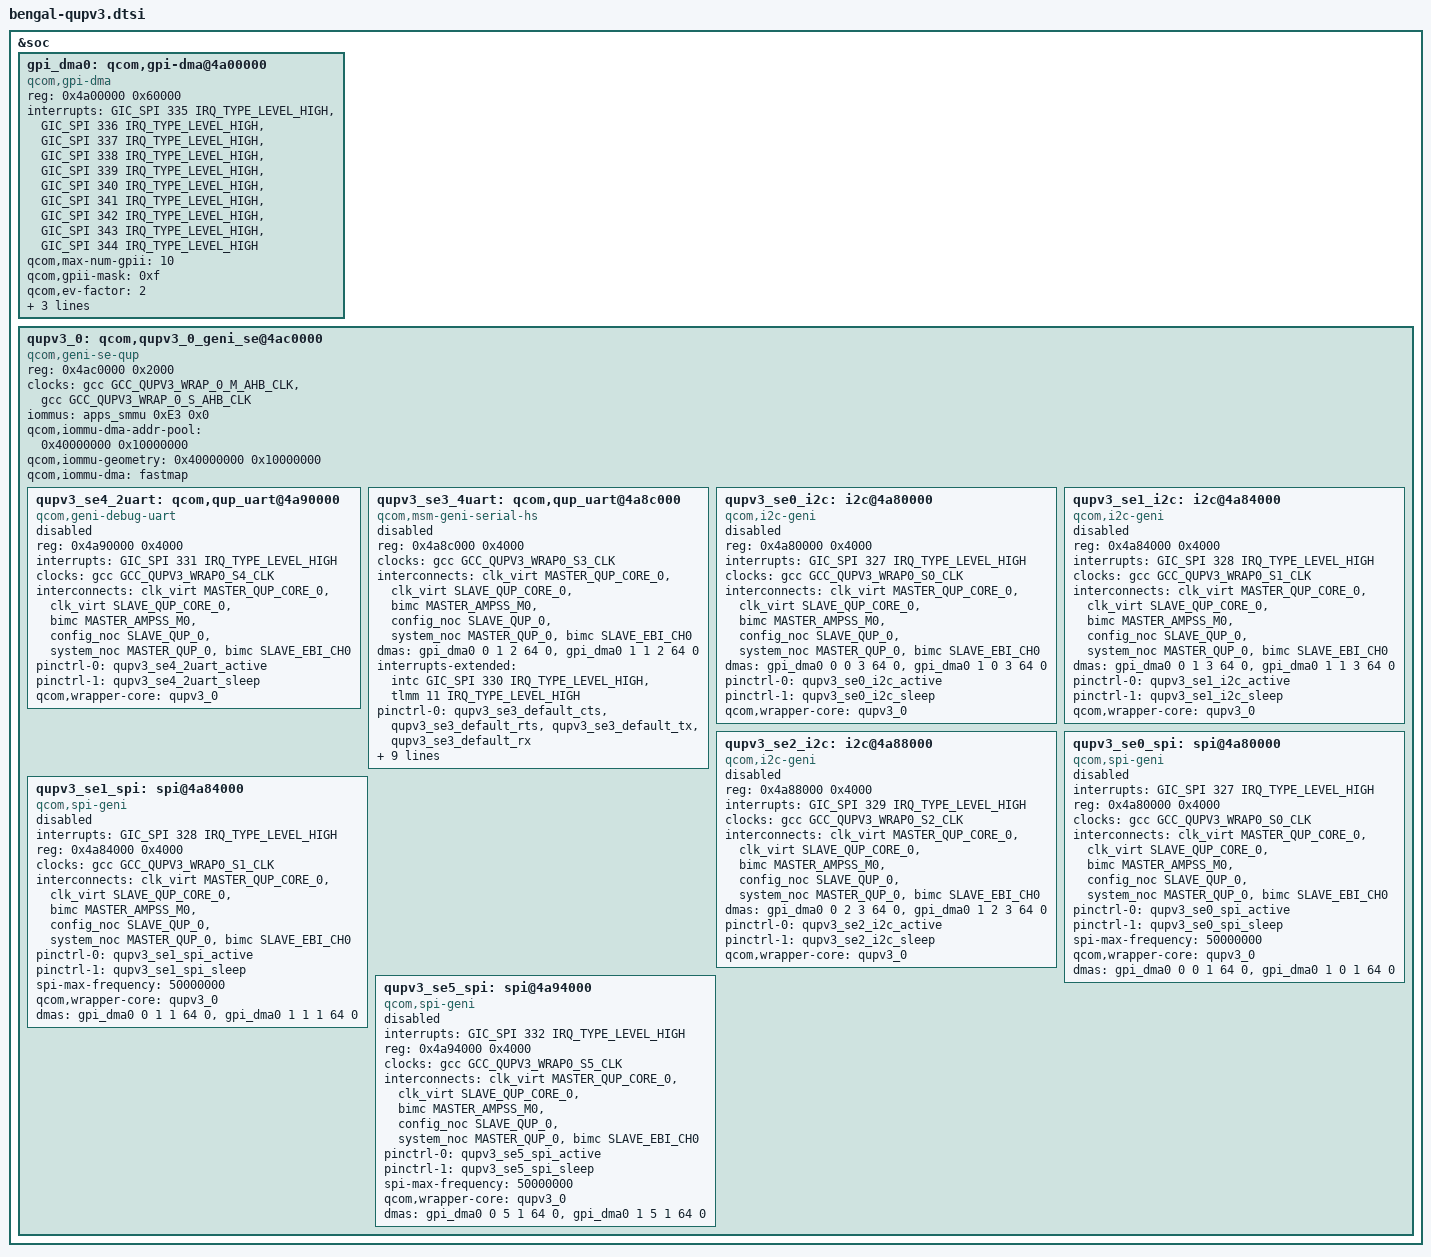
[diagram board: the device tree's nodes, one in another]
&soc {

	/* GPI Instance */
	gpi_dma0: qcom,gpi-dma@4a00000 {
		compatible = "qcom,gpi-dma";
		#dma-cells = <5>;
		reg = <0x4a00000 0x60000>;
		reg-names = "gpi-top";
		interrupts = <GIC_SPI 335 IRQ_TYPE_LEVEL_HIGH>,
			<GIC_SPI 336 IRQ_TYPE_LEVEL_HIGH>,
			<GIC_SPI 337 IRQ_TYPE_LEVEL_HIGH>,
			<GIC_SPI 338 IRQ_TYPE_LEVEL_HIGH>,
			<GIC_SPI 339 IRQ_TYPE_LEVEL_HIGH>,
			<GIC_SPI 340 IRQ_TYPE_LEVEL_HIGH>,
			<GIC_SPI 341 IRQ_TYPE_LEVEL_HIGH>,
			<GIC_SPI 342 IRQ_TYPE_LEVEL_HIGH>,
			<GIC_SPI 343 IRQ_TYPE_LEVEL_HIGH>,
			<GIC_SPI 344 IRQ_TYPE_LEVEL_HIGH>;
		qcom,max-num-gpii = <10>;
		qcom,gpii-mask = <0xf>;
		qcom,ev-factor = <2>;
		iommus = <&apps_smmu 0xf6 0x0>;
		qcom,gpi-ee-offset = <0x10000>;
		qcom,iommu-dma-addr-pool = <0x100000 0x100000>;
		status = "ok";
	};

	/* QUPv3_0  wrapper  instance */
	qupv3_0: qcom,qupv3_0_geni_se@4ac0000 {
		compatible = "qcom,geni-se-qup";
		reg = <0x4ac0000 0x2000>;
		#address-cells = <1>;
		#size-cells = <1>;
		clock-names = "m-ahb", "s-ahb";
		clocks = <&gcc GCC_QUPV3_WRAP_0_M_AHB_CLK>,
			<&gcc GCC_QUPV3_WRAP_0_S_AHB_CLK>;
		iommus = <&apps_smmu 0xE3 0x0>;
		qcom,iommu-dma-addr-pool = <0x40000000 0x10000000>;
		qcom,iommu-geometry = <0x40000000 0x10000000>;
		qcom,iommu-dma = "fastmap";
		ranges;
		status = "ok";

		/* Debug UART Instance */
		qupv3_se4_2uart: qcom,qup_uart@4a90000 {
			compatible = "qcom,geni-debug-uart";
			reg = <0x4a90000 0x4000>;
			reg-names = "se_phys";
			interrupts = <GIC_SPI 331 IRQ_TYPE_LEVEL_HIGH>;
			clock-names = "se";
			clocks = <&gcc GCC_QUPV3_WRAP0_S4_CLK>;
			interconnect-names = "qup-core", "qup-config", "qup-memory";
			interconnects = <&clk_virt MASTER_QUP_CORE_0 &clk_virt SLAVE_QUP_CORE_0>,
			<&bimc MASTER_AMPSS_M0 &config_noc SLAVE_QUP_0>,
			<&system_noc MASTER_QUP_0 &bimc SLAVE_EBI_CH0>;
			pinctrl-names = "default", "sleep";
			pinctrl-0 = <&qupv3_se4_2uart_active>;
			pinctrl-1 = <&qupv3_se4_2uart_sleep>;
			qcom,wrapper-core = <&qupv3_0>;
			status = "disabled";
		};

		/* HS UART Instance */
		qupv3_se3_4uart: qcom,qup_uart@4a8c000 {
			compatible = "qcom,msm-geni-serial-hs";
			reg = <0x4a8c000 0x4000>;
			reg-names = "se_phys";
			clock-names = "se-clk";
			clocks = <&gcc GCC_QUPV3_WRAP0_S3_CLK>;
			interconnect-names = "qup-core", "qup-config", "qup-memory";
			interconnects = <&clk_virt MASTER_QUP_CORE_0 &clk_virt SLAVE_QUP_CORE_0>,
			<&bimc MASTER_AMPSS_M0 &config_noc SLAVE_QUP_0>,
			<&system_noc MASTER_QUP_0 &bimc SLAVE_EBI_CH0>;
			dmas = <&gpi_dma0 0 1 2 64 0>,
			<&gpi_dma0 1 1 2 64 0>;
			dma-names = "tx", "rx";
			pinctrl-names = "default", "active", "sleep", "shutdown";
			interrupts-extended = <&intc GIC_SPI 330 IRQ_TYPE_LEVEL_HIGH>,
					<&tlmm 11 IRQ_TYPE_LEVEL_HIGH>;
			pinctrl-0 = <&qupv3_se3_default_cts>, <&qupv3_se3_default_rts>,
				<&qupv3_se3_default_tx>, <&qupv3_se3_default_rx>;
			pinctrl-1 = <&qupv3_se3_cts>, <&qupv3_se3_rts>,
				<&qupv3_se3_tx>, <&qupv3_se3_rx>;
			pinctrl-2 = <&qupv3_se3_cts>, <&qupv3_se3_rts>,
				<&qupv3_se3_tx>, <&qupv3_se3_default_rx>;
			pinctrl-3 = <&qupv3_se3_default_cts>, <&qupv3_se3_default_rts>,
				<&qupv3_se3_default_tx>, <&qupv3_se3_default_rx>;
			qcom,wrapper-core = <&qupv3_0>;
			qcom,wakeup-byte = <0xFD>;
			status = "disabled";
		};

		/* I2C Instance */
		qupv3_se0_i2c: i2c@4a80000 {
			compatible = "qcom,i2c-geni";
			reg = <0x4a80000 0x4000>;
			#address-cells = <1>;
			#size-cells = <0>;
			interrupts = <GIC_SPI 327 IRQ_TYPE_LEVEL_HIGH>;
			clock-names = "se-clk";
			clocks = <&gcc GCC_QUPV3_WRAP0_S0_CLK>;
			interconnect-names = "qup-core", "qup-config", "qup-memory";
			interconnects = <&clk_virt MASTER_QUP_CORE_0 &clk_virt SLAVE_QUP_CORE_0>,
			<&bimc MASTER_AMPSS_M0 &config_noc SLAVE_QUP_0>,
			<&system_noc MASTER_QUP_0 &bimc SLAVE_EBI_CH0>;
			dmas = <&gpi_dma0 0 0 3 64 0>,
				<&gpi_dma0 1 0 3 64 0>;
			dma-names = "tx", "rx";
			pinctrl-names = "default", "sleep";
			pinctrl-0 = <&qupv3_se0_i2c_active>;
			pinctrl-1 = <&qupv3_se0_i2c_sleep>;
			qcom,wrapper-core = <&qupv3_0>;
			status = "disabled";
		};

		/* I2C Instance */
		qupv3_se1_i2c: i2c@4a84000 {
			compatible = "qcom,i2c-geni";
			reg = <0x4a84000 0x4000>;
			#address-cells = <1>;
			#size-cells = <0>;
			interrupts = <GIC_SPI 328 IRQ_TYPE_LEVEL_HIGH>;
			clock-names = "se-clk";
			clocks = <&gcc GCC_QUPV3_WRAP0_S1_CLK>;
			interconnect-names = "qup-core", "qup-config", "qup-memory";
			interconnects = <&clk_virt MASTER_QUP_CORE_0 &clk_virt SLAVE_QUP_CORE_0>,
			<&bimc MASTER_AMPSS_M0 &config_noc SLAVE_QUP_0>,
			<&system_noc MASTER_QUP_0 &bimc SLAVE_EBI_CH0>;
			dmas = <&gpi_dma0 0 1 3 64 0>,
				<&gpi_dma0 1 1 3 64 0>;
			dma-names = "tx", "rx";
			pinctrl-names = "default", "sleep";
			pinctrl-0 = <&qupv3_se1_i2c_active>;
			pinctrl-1 = <&qupv3_se1_i2c_sleep>;
			qcom,wrapper-core = <&qupv3_0>;
			status = "disabled";
		};

		/* I2C Instance */
		qupv3_se2_i2c: i2c@4a88000 {
			compatible = "qcom,i2c-geni";
			reg = <0x4a88000 0x4000>;
			#address-cells = <1>;
			#size-cells = <0>;
			interrupts = <GIC_SPI 329 IRQ_TYPE_LEVEL_HIGH>;
			clock-names = "se-clk";
			clocks = <&gcc GCC_QUPV3_WRAP0_S2_CLK>;
			interconnect-names = "qup-core", "qup-config", "qup-memory";
			interconnects = <&clk_virt MASTER_QUP_CORE_0 &clk_virt SLAVE_QUP_CORE_0>,
			<&bimc MASTER_AMPSS_M0 &config_noc SLAVE_QUP_0>,
			<&system_noc MASTER_QUP_0 &bimc SLAVE_EBI_CH0>;
			dmas = <&gpi_dma0 0 2 3 64 0>,
				<&gpi_dma0 1 2 3 64 0>;
			dma-names = "tx", "rx";
			pinctrl-names = "default", "sleep";
			pinctrl-0 = <&qupv3_se2_i2c_active>;
			pinctrl-1 = <&qupv3_se2_i2c_sleep>;
			qcom,wrapper-core = <&qupv3_0>;
			status = "disabled";
		};

		/* SPI Instance */
		qupv3_se0_spi: spi@4a80000 {
			compatible = "qcom,spi-geni";
			#address-cells = <1>;
			#size-cells = <0>;
			interrupts = <GIC_SPI 327 IRQ_TYPE_LEVEL_HIGH>;
			reg = <0x4a80000 0x4000>;
			reg-names = "se_phys";
			clock-names = "se-clk";
			clocks = <&gcc GCC_QUPV3_WRAP0_S0_CLK>;
			interconnect-names = "qup-core", "qup-config", "qup-memory";
			interconnects = <&clk_virt MASTER_QUP_CORE_0 &clk_virt SLAVE_QUP_CORE_0>,
			<&bimc MASTER_AMPSS_M0 &config_noc SLAVE_QUP_0>,
			<&system_noc MASTER_QUP_0 &bimc SLAVE_EBI_CH0>;
			pinctrl-names = "default", "sleep";
			pinctrl-0 = <&qupv3_se0_spi_active>;
			pinctrl-1 = <&qupv3_se0_spi_sleep>;
			spi-max-frequency = <50000000>;
			qcom,wrapper-core = <&qupv3_0>;
			dmas = <&gpi_dma0 0 0 1 64 0>,
				<&gpi_dma0 1 0 1 64 0>;
			dma-names = "tx", "rx";
			status = "disabled";
		};

		/* SPI Instance */
		qupv3_se1_spi: spi@4a84000 {
			compatible = "qcom,spi-geni";
			#address-cells = <1>;
			#size-cells = <0>;
			interrupts = <GIC_SPI 328 IRQ_TYPE_LEVEL_HIGH>;
			reg = <0x4a84000 0x4000>;
			reg-names = "se_phys";
			clock-names = "se-clk";
			clocks = <&gcc GCC_QUPV3_WRAP0_S1_CLK>;
			interconnect-names = "qup-core", "qup-config", "qup-memory";
			interconnects = <&clk_virt MASTER_QUP_CORE_0 &clk_virt SLAVE_QUP_CORE_0>,
			<&bimc MASTER_AMPSS_M0 &config_noc SLAVE_QUP_0>,
			<&system_noc MASTER_QUP_0 &bimc SLAVE_EBI_CH0>;
			pinctrl-names = "default", "sleep";
			pinctrl-0 = <&qupv3_se1_spi_active>;
			pinctrl-1 = <&qupv3_se1_spi_sleep>;
			spi-max-frequency = <50000000>;
			qcom,wrapper-core = <&qupv3_0>;
			dmas = <&gpi_dma0 0 1 1 64 0>,
				<&gpi_dma0 1 1 1 64 0>;
			dma-names = "tx", "rx";
			status = "disabled";
		};

		/* SPI Instance */
		qupv3_se5_spi: spi@4a94000 {
			compatible = "qcom,spi-geni";
			#address-cells = <1>;
			#size-cells = <0>;
			interrupts = <GIC_SPI 332 IRQ_TYPE_LEVEL_HIGH>;
			reg = <0x4a94000 0x4000>;
			reg-names = "se_phys";
			clock-names = "se-clk";
			clocks = <&gcc GCC_QUPV3_WRAP0_S5_CLK>;
			interconnect-names = "qup-core", "qup-config", "qup-memory";
			interconnects = <&clk_virt MASTER_QUP_CORE_0 &clk_virt SLAVE_QUP_CORE_0>,
			<&bimc MASTER_AMPSS_M0 &config_noc SLAVE_QUP_0>,
			<&system_noc MASTER_QUP_0 &bimc SLAVE_EBI_CH0>;
			pinctrl-names = "default", "sleep";
			pinctrl-0 = <&qupv3_se5_spi_active>;
			pinctrl-1 = <&qupv3_se5_spi_sleep>;
			spi-max-frequency = <50000000>;
			qcom,wrapper-core = <&qupv3_0>;
			dmas = <&gpi_dma0 0 5 1 64 0>,
				<&gpi_dma0 1 5 1 64 0>;
			dma-names = "tx", "rx";
			status = "disabled";
		};
	};
};
